# MSP430FR2476 register map
Vendor: msp430gen; File version: v0.4.0-28-gb0087ce-dirty
Registers are 16-bit, read-write, reset 0x0 unless marked. A register's access mark holds for its fields unless they carry their own. Offsets are from the block's base; [hi:lo] are bit positions; lines under a group give offsets from that group; {n}, {i} and the like mark numbered series.

## TB0
Base 0x00000480
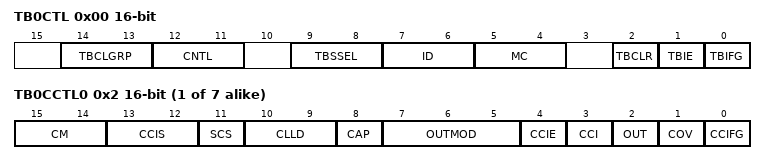
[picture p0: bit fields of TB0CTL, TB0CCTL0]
0x00 TB0CTL — Timer_B Control Register
  [14:13] TBCLGRP — TBxCLn group
    0=Each TBxCLn latch loads independently; 1=TBxCL1+TBxCL2 (TBxCCR1 CLLD bits control the update); TBxCL3+TBxCL4 (TBxCCR3 CLLD bits control the update); TBxCL5+TBxCL6 (TBxCCR5 CLLD bits control the update); TBxCL0 independent; 2=TBxCL1+TBxCL2+TBxCL3 (TBxCCR1 CLLD bits control the update); TBxCL4+TBxCL5+TBxCL6 (TBxCCR4 CLLD bits control the update); TBxCL0 independent; 3=TBxCL0+TBxCL1+TBxCL2+TBxCL3+TBxCL4+TBxCL5+TBxCL6 (TBxCCR1 CLLD bits control the update)
  [12:11] CNTL — Counter length
    0=16-bit, TBxR(max) = 0FFFFh; 1=12-bit, TBxR(max) = 0FFFh; 2=10-bit, TBxR(max) = 03FFh; 3=8-bit, TBxR(max) = 0FFh
  [9:8] TBSSEL — TimerB clock source select
    0=TBCLK (TBxCLK); 1=ACLK; 2=SMCLK; 3=INCLK
  [7:6] ID — Input divider
    0=1; 1=2; 2=4; 3=8
  [5:4] MC — Mode control
    0=STOP (Stop mode: Timer is halted); 1=UP (Up mode: Timer counts up to TBxCL0); 2=CONTINUOUS (Continuous mode: Timer counts up to the value set by CNTL); 3=UPDOWN (Up/down mode: Timer counts up to TBxCL0 then down to 0000h)
  [2] TBCLR — TimerB clear
  [1] TBIE — TimerB interrupt enable
    0=Interrupt disabled; 1=Interrupt enabled
  [0] TBIFG — TimerB interrupt flag
    0=No interrupt pending; 1=Interrupt pending
{0x2+2i} TB0CCTL{i} (i=0..6) — Timer_B Capture/Compare Control Register
  [15:14] CM — Capture mode
    0=NONE (No capture); 1=RISING (Capture on rising edge); 2=FALLING (Capture on falling edge); 3=BOTH (Capture on both rising and falling edges)
  [13:12] CCIS — Capture/compare input select
    0=CCIA (CCIxA); 1=CCIB (CCIxB); 2=GND; 3=VCC
  [11] SCS — Synchronize capture source
    0=ASYNC (Asynchronous capture); 1=SYNC (Synchronous capture)
  [10:9] CLLD — Compare latch load
    0=TBxCLn loads on write to TBxCCRn; 1=TBxCLn loads when TBxR counts to 0; 2=TBxCLn loads when TBxR counts to 0 (up or continuous mode). TBxCLn loads when TBxR counts to TBxCL0 or to 0 (up/down mode).; 3=TBxCLn loads when TBxR counts to TBxCLn
  [8] CAP — Capture mode
    0=COMPARE (Compare mode); 1=CAPTURE (Capture mode)
  [7:5] OUTMOD — Output mode
    0=OUT bit value; 1=Set; 2=Toggle/reset; 3=Set/reset; 4=Toggle; 5=Reset; 6=Toggle/set; 7=Reset/set
  [4] CCIE — Capture/compare interrupt enable
    0=Interrupt disabled; 1=Interrupt enabled
  [3] CCI ro — Capture/compare input
  [2] OUT — Output
    0=LOW (Output low); 1=HIGH (Output high)
  [1] COV — Capture overflow
    0=No capture overflow occurred; 1=Capture overflow occurred
  [0] CCIFG — Capture/compare interrupt flag
    0=No interrupt pending; 1=Interrupt pending
0x10 TB0R — Timer_B count register
{0x12+2i} TB0CCR{i} (i=0..6) — Timer_B Capture/Compare Register
0x20 TB0EX0 — Timer_Bx Expansion Register 0
  [2:0] TBIDEX — Input divider expansion
    {v}=Divide by {v+1} (v=0..7)
0x2E TB0IV — Timer_Bx Interrupt Vector Register
  [15:0] TBIV ro — Timer_B interrupt vector value
    0=NONE (No interrupt pending); 2=TBCCR1 (Interrupt Source: Capture/compare 1; Interrupt Flag: TBxCCR1 CCIFG; Interrupt Priority: Highest); 4=TBCCR2 (Interrupt Source: Capture/compare 2; Interrupt Flag: TBxCCR2 CCIFG); 6=TBCCR3 (Interrupt Source: Capture/compare 3; Interrupt Flag: TBxCCR3 CCIFG); 8=TBCCR4 (Interrupt Source: Capture/compare 4; Interrupt Flag: TBxCCR4 CCIFG); 10=TBCCR5 (Interrupt Source: Capture/compare 5; Interrupt Flag: TBxCCR5 CCIFG); 12=TBCCR6 (Interrupt Source: Capture/compare 6; Interrupt Flag: TBxCCR6 CCIFG); 14=TBIFG (Interrupt Source: Timer overflow; Interrupt Flag: TBxCTL TBIFG; Interrupt Priority: Lowest)

## MPY32
Base 0x000004C0
0x00 MPY — 16-bit operand one multiply
0x02 MPYS — 16-bit operand one signed multiply
0x04 MAC — 16-bit operand one multiply accumulate
0x06 MACS — 16-bit operand one signed multiply accumulate
0x08 OP2 — 16-bit operand two
0x0A RESLO — 16x16-bit result low word
0x0C RESHI — 16x16-bit result high word
0x0E SUMEXT — 16x16-bit sum extension register
0x10 MPY32L — 32-bit operand 1 multiply low word
0x12 MPY32H — 32-bit operand 1 multiply high word
0x14 MPYS32L — 32-bit operand 1 signed multiply low word
0x16 MPYS32H — 32-bit operand 1 signed multiply high word
0x18 MAC32L — 32-bit operand 1 multiply accumulate low word
0x1A MAC32H — 32-bit operand 1 multiply accumulate high word
0x1C MACS32L — 32-bit operand 1 signed multiply accumulate low word
0x1E MACS32H — 32-bit operand 1 signed multiply accumulate high word
0x20 OP2L — 32-bit operand 2 low word
0x22 OP2H — 32-bit operand 2 high word
0x24 RES0 — 32x32-bit result 0 least significant word
0x26 RES1 — 32x32-bit result 1
0x28 RES2 — 32x32-bit result 2
0x2A RES3 — 32x32-bit result 3 most significant word
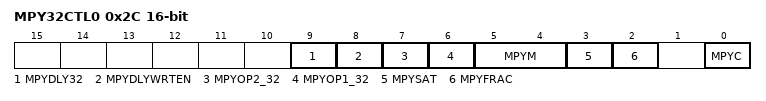
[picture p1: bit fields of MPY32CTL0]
0x2C MPY32CTL0 — MPY32 control register 0
  [9] MPYDLY32 — Delayed write mode.
    0=Writes are delayed until 64-bit result (RES0 to RES3) is available; 1=Writes are delayed until 32-bit result (RES0 to RES1) is available. 8 MPYDLYWRTEN
  [8] MPYDLYWRTEN — Delayed write enable.
    0=Writes are not delayed; 1=Writes are delayed
  [7] MPYOP2_32 — Multiplier bit width of operand 2
    0=16 bits; 1=32 bits
  [6] MPYOP1_32 — Multiplier bit width of operand 1
    0=16 bits; 1=32 bits
  [5:4] MPYM — Multiplier mode
    0=MPY (MPY Multiply); 1=MPYS (MPYS Signed multiply); 2=MAC (MAC Multiply accumulate); 3=MACS (MACS Signed multiply accumulate)
  [3] MPYSAT — Saturation mode
    0=DISABLE (Saturation mode disabled.); 1=ENABLE (Saturation mode enabled.)
  [2] MPYFRAC — Fractional mode.
    0=DISABLE (Fractional mode disabled.); 1=ENABLE (Fractional mode enabled.)
  [0] MPYC — Carry of the multiplier
    0=No carry for result; 1=Result has a carry
